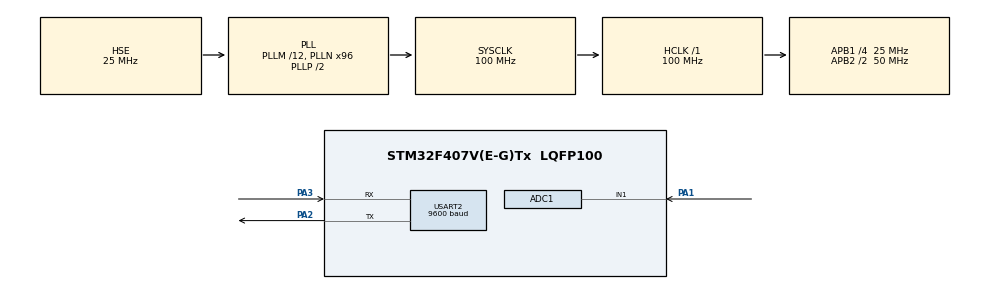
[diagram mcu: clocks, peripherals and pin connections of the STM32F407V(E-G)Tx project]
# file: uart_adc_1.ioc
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ADC1.Channel-0\#ChannelRegularConversion=ADC_CHANNEL_1
ADC1.EOCSelection=ADC_EOC_SEQ_CONV
ADC1.NbrOfConversionFlag=1
ADC1.Rank-0\#ChannelRegularConversion=1
ADC1.SamplingTime-0\#ChannelRegularConversion=ADC_SAMPLETIME_144CYCLES
ADC1.master=1
Mcu.Family=STM32F4
Mcu.Name=STM32F407V(E-G)Tx
Mcu.Package=LQFP100
NVIC.ADC_IRQn=true\:0\:0\:false\:false\:true\:true
NVIC.PriorityGroup=NVIC_PRIORITYGROUP_4
NVIC.USART2_IRQn=true\:0\:0\:false\:false\:true\:true
PA1.Signal=ADCx_IN1
PA2.Mode=Asynchronous
PA2.Signal=USART2_TX
PA3.Mode=Asynchronous
PA3.Signal=USART2_RX
PH0-OSC_IN.Mode=HSE-External-Oscillator
PH0-OSC_IN.Signal=RCC_OSC_IN
PH1-OSC_OUT.Mode=HSE-External-Oscillator
PH1-OSC_OUT.Signal=RCC_OSC_OUT
ProjectManager.HeapSize=0x200
ProjectManager.StackSize=0x400
ProjectManager.TargetToolchain=TrueSTUDIO
RCC.48MHZClocksFreq_Value=50000000
RCC.AHBFreq_Value=100000000
RCC.APB1CLKDivider=RCC_HCLK_DIV4
RCC.APB1Freq_Value=25000000
RCC.APB1TimFreq_Value=50000000
RCC.APB2CLKDivider=RCC_HCLK_DIV2
RCC.APB2Freq_Value=50000000
RCC.APB2TimFreq_Value=100000000
RCC.CortexFreq_Value=100000000
RCC.HCLKFreq_Value=100000000
RCC.HSE_VALUE=25000000
RCC.HSI_VALUE=16000000
RCC.LSE_VALUE=32768
RCC.PLLM=12
RCC.PLLN=96
RCC.PLLSourceVirtual=RCC_PLLSOURCE_HSE
RCC.SYSCLKFreq_VALUE=100000000
RCC.SYSCLKSource=RCC_SYSCLKSOURCE_PLLCLK
RCC.VCOOutputFreq_Value=200000000
SH.ADCx_IN1.0=ADC1_IN1,IN1
USART2.BaudRate=9600
USART2.VirtualMode=VM_ASYNC
board=uart_adc_1

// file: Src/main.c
/**
  ******************************************************************************
  * File Name          : main.c
  * Description        : Main program body
  ******************************************************************************
  ** This notice applies to any and all portions of this file
  * that are not between comment pairs USER CODE BEGIN and
  * USER CODE END. Other portions of this file, whether
  * inserted by the user or by software development tools
  * are owned by their respective copyright owners.
  *
  * COPYRIGHT(c) 2018 STMicroelectronics
  *
  * Redistribution and use in source and binary forms, with or without modification,
  * are permitted provided that the following conditions are met:
  *   1. Redistributions of source code must retain the above copyright notice,
  *      this list of conditions and the following disclaimer.
  *   2. Redistributions in binary form must reproduce the above copyright notice,
  *      this list of conditions and the following disclaimer in the documentation
  *      and/or other materials provided with the distribution.
  *   3. Neither the name of STMicroelectronics nor the names of its contributors
  *      may be used to endorse or promote products derived from this software
  *      without specific prior written permission.
  *
  * THIS SOFTWARE IS PROVIDED BY THE COPYRIGHT HOLDERS AND CONTRIBUTORS "AS IS"
  * AND ANY EXPRESS OR IMPLIED WARRANTIES, INCLUDING, BUT NOT LIMITED TO, THE
  * IMPLIED WARRANTIES OF MERCHANTABILITY AND FITNESS FOR A PARTICULAR PURPOSE ARE
  * DISCLAIMED. IN NO EVENT SHALL THE COPYRIGHT HOLDER OR CONTRIBUTORS BE LIABLE
  * FOR ANY DIRECT, INDIRECT, INCIDENTAL, SPECIAL, EXEMPLARY, OR CONSEQUENTIAL
  * DAMAGES (INCLUDING, BUT NOT LIMITED TO, PROCUREMENT OF SUBSTITUTE GOODS OR
  * SERVICES; LOSS OF USE, DATA, OR PROFITS; OR BUSINESS INTERRUPTION) HOWEVER
  * CAUSED AND ON ANY THEORY OF LIABILITY, WHETHER IN CONTRACT, STRICT LIABILITY,
  * OR TORT (INCLUDING NEGLIGENCE OR OTHERWISE) ARISING IN ANY WAY OUT OF THE USE
  * OF THIS SOFTWARE, EVEN IF ADVISED OF THE POSSIBILITY OF SUCH DAMAGE.
  *
  ******************************************************************************
  */

#include "main.h"
#include "stm32f4xx_hal.h"

/* USER CODE BEGIN Includes */

#define      M_TX_TASK          0
#define      M_RX_TASK          1
#define      M_TX_RX_TASK       2
#define      M_TASK1            3
#define      M_TASK2            4
#define      M_TASK3            5
#define      M_TASK4            6
#define      M_TASKS_UART       M_TASK4

/* USER CODE END Includes */

ADC_HandleTypeDef hadc1;

UART_HandleTypeDef huart2;

/* USER CODE BEGIN PV */
/* Private variables ---------------------------------------------------------*/

/* USER CODE END PV */

void SystemClock_Config(void);
static void MX_GPIO_Init(void);
static void MX_ADC1_Init(void);
static void MX_USART2_UART_Init(void);

/* USER CODE BEGIN PFP */
/* Private function prototypes -----------------------------------------------*/

/* USER CODE END PFP */

/* USER CODE BEGIN 0 */

uint16_t v_adcData_u16;
uint8_t a_rxBuffer_u8[20] = {0};

uint8_t i;

uint8_t* varToStrConv(uint16_t v_var_u16, uint8_t v_size_u8)
{
	static uint8_t p_string_u8[1000]= {0};
	int8_t v_cnt_u8;
	p_string_u8[v_size_u8 - 1] = '\n';
	for(v_cnt_u8 = (v_size_u8 - 2); v_cnt_u8 >= 0; v_cnt_u8--)
	{
	p_string_u8[v_cnt_u8] = ((v_var_u16 % 10) + 48);
	v_var_u16 /= 10;
	}

	return p_string_u8;
}

void HAL_ADC_ConvCpltCallback(ADC_HandleTypeDef* hadc)
{
	v_adcData_u16 = HAL_ADC_GetValue(hadc);
}

void HAL_UART_TxCpltCallback(UART_HandleTypeDef *huart)
{
	i++;
}
/* USER CODE END 0 */

int main(void)
{

  /* USER CODE BEGIN 1 */
uint8_t indx = 0;
uint16_t v_counter4Dig_u32 = 0;
  /* USER CODE END 1 */

  /* MCU Configuration----------------------------------------------------------*/

  /* Reset of all peripherals, Initializes the Flash interface and the Systick. */
  HAL_Init();

  /* Configure the system clock */
  SystemClock_Config();

  /* Initialize all configured peripherals */
  MX_GPIO_Init();
  MX_ADC1_Init();
  MX_USART2_UART_Init();

  /* USER CODE BEGIN 2 */

  HAL_ADC_Start_IT(&hadc1);

  /* USER CODE END 2 */

  /* Infinite loop */
  while (1)
  {

  /* USER CODE BEGIN 3 */
#if(M_TASKS_UART == M_TX_TASK)
	  {
	   HAL_UART_Transmit_IT(&huart2, "hello\n", 6);

	  }
#endif

#if(M_TASKS_UART == M_RX_TASK)
	  {
	  HAL_UART_Receive_IT(&huart2, a_rxBuffer_u8, 20);
	  for(indx = 0; indx < 20 ; indx++)
	  {
		if(a_rxBuffer_u8[indx]  == 0)
			a_rxBuffer_u8[indx] = ' ';
	  }
	  a_rxBuffer_u8[19] = '\n';
	  HAL_UART_Transmit_IT(&huart2,a_rxBuffer_u8 , 20);
	  HAL_Delay(1000);
	  }
#endif

#if(M_TASKS_UART == M_TX_RX_TASK)
	  {
	   HAL_UART_Transmit_IT(&huart2, "hello\n", 6);
	   HAL_Delay(500);
	  HAL_UART_Receive_IT(&huart2, a_rxBuffer_u8, 20);
	  for(indx = 0; indx < 20 ; indx++)
	  {
		if(a_rxBuffer_u8[indx]  == 0)
			a_rxBuffer_u8[indx] = ' ';
	  }
	  a_rxBuffer_u8[19] = '\n';
	  HAL_UART_Transmit_IT(&huart2,a_rxBuffer_u8 , 20);
	  HAL_Delay(500);
	  }
#endif

#if(M_TASKS_UART == M_TASK1)
	  {
		  HAL_UART_Transmit_IT(&huart2, "hello\n", 6);
		  HAL_Delay(100);
	  }
#endif

#if(M_TASKS_UART == M_TASK2)
	  {
		  HAL_UART_Transmit_IT(&huart2, varToStrConv(v_counter4Dig_u32++,5), 5);
		  HAL_Delay(100);
	  }
#endif

#if(M_TASKS_UART == M_TASK3)
	  {
		  HAL_UART_Receive_IT(&huart2, a_rxBuffer_u8, 1);
		  HAL_UART_Transmit_IT(&huart2, varToStrConv(a_rxBuffer_u8[0],4), 4);
		  HAL_Delay(100);
	  }
#endif

#if(M_TASKS_UART == M_TASK4)
	  {
		  HAL_UART_Transmit_IT(&huart2, "hello\n", 6);
		  //varToStrConv(v_adcData_u16, 5)
	  }
#endif

  }
  /* USER CODE END 3 */

}

/** System Clock Configuration
*/
void SystemClock_Config(void)
{

  RCC_OscInitTypeDef RCC_OscInitStruct;
  RCC_ClkInitTypeDef RCC_ClkInitStruct;

    /**Configure the main internal regulator output voltage
    */
  __HAL_RCC_PWR_CLK_ENABLE();

  __HAL_PWR_VOLTAGESCALING_CONFIG(PWR_REGULATOR_VOLTAGE_SCALE1);

    /**Initializes the CPU, AHB and APB busses clocks
    */
  RCC_OscInitStruct.OscillatorType = RCC_OSCILLATORTYPE_HSE;
  RCC_OscInitStruct.HSEState = RCC_HSE_ON;
  RCC_OscInitStruct.PLL.PLLState = RCC_PLL_ON;
  RCC_OscInitStruct.PLL.PLLSource = RCC_PLLSOURCE_HSE;
  RCC_OscInitStruct.PLL.PLLM = 12;
  RCC_OscInitStruct.PLL.PLLN = 96;
  RCC_OscInitStruct.PLL.PLLP = RCC_PLLP_DIV2;
  RCC_OscInitStruct.PLL.PLLQ = 4;
  if (HAL_RCC_OscConfig(&RCC_OscInitStruct) != HAL_OK)
  {
    _Error_Handler(__FILE__, __LINE__);
  }

    /**Initializes the CPU, AHB and APB busses clocks
    */
  RCC_ClkInitStruct.ClockType = RCC_CLOCKTYPE_HCLK|RCC_CLOCKTYPE_SYSCLK
                              |RCC_CLOCKTYPE_PCLK1|RCC_CLOCKTYPE_PCLK2;
  RCC_ClkInitStruct.SYSCLKSource = RCC_SYSCLKSOURCE_PLLCLK;
  RCC_ClkInitStruct.AHBCLKDivider = RCC_SYSCLK_DIV1;
  RCC_ClkInitStruct.APB1CLKDivider = RCC_HCLK_DIV4;
  RCC_ClkInitStruct.APB2CLKDivider = RCC_HCLK_DIV2;

  if (HAL_RCC_ClockConfig(&RCC_ClkInitStruct, FLASH_LATENCY_3) != HAL_OK)
  {
    _Error_Handler(__FILE__, __LINE__);
  }

    /**Configure the Systick interrupt time
    */
  HAL_SYSTICK_Config(HAL_RCC_GetHCLKFreq()/1000);

    /**Configure the Systick
    */
  HAL_SYSTICK_CLKSourceConfig(SYSTICK_CLKSOURCE_HCLK);

  /* SysTick_IRQn interrupt configuration */
  HAL_NVIC_SetPriority(SysTick_IRQn, 0, 0);
}

/* ADC1 init function */
static void MX_ADC1_Init(void)
{

  ADC_ChannelConfTypeDef sConfig;

    /**Configure the global features of the ADC (Clock, Resolution, Data Alignment and number of conversion)
    */
  hadc1.Instance = ADC1;
  hadc1.Init.ClockPrescaler = ADC_CLOCK_SYNC_PCLK_DIV2;
  hadc1.Init.Resolution = ADC_RESOLUTION_12B;
  hadc1.Init.ScanConvMode = DISABLE;
  hadc1.Init.ContinuousConvMode = DISABLE;
  hadc1.Init.DiscontinuousConvMode = DISABLE;
  hadc1.Init.ExternalTrigConvEdge = ADC_EXTERNALTRIGCONVEDGE_NONE;
  hadc1.Init.ExternalTrigConv = ADC_SOFTWARE_START;
  hadc1.Init.DataAlign = ADC_DATAALIGN_RIGHT;
  hadc1.Init.NbrOfConversion = 1;
  hadc1.Init.DMAContinuousRequests = DISABLE;
  hadc1.Init.EOCSelection = ADC_EOC_SEQ_CONV;
  if (HAL_ADC_Init(&hadc1) != HAL_OK)
  {
    _Error_Handler(__FILE__, __LINE__);
  }

    /**Configure for the selected ADC regular channel its corresponding rank in the sequencer and its sample time.
    */
  sConfig.Channel = ADC_CHANNEL_1;
  sConfig.Rank = 1;
  sConfig.SamplingTime = ADC_SAMPLETIME_144CYCLES;
  if (HAL_ADC_ConfigChannel(&hadc1, &sConfig) != HAL_OK)
  {
    _Error_Handler(__FILE__, __LINE__);
  }

}

/* USART2 init function */
static void MX_USART2_UART_Init(void)
{

  huart2.Instance = USART2;
  huart2.Init.BaudRate = 9600;
  huart2.Init.WordLength = UART_WORDLENGTH_8B;
  huart2.Init.StopBits = UART_STOPBITS_1;
  huart2.Init.Parity = UART_PARITY_NONE;
  huart2.Init.Mode = UART_MODE_TX_RX;
  huart2.Init.HwFlowCtl = UART_HWCONTROL_NONE;
  huart2.Init.OverSampling = UART_OVERSAMPLING_16;
  if (HAL_UART_Init(&huart2) != HAL_OK)
  {
    _Error_Handler(__FILE__, __LINE__);
  }

}

/** Configure pins as
        * Analog
        * Input
        * Output
        * EVENT_OUT
        * EXTI
*/
static void MX_GPIO_Init(void)
{

  /* GPIO Ports Clock Enable */
  __HAL_RCC_GPIOH_CLK_ENABLE();
  __HAL_RCC_GPIOA_CLK_ENABLE();

}

void _Error_Handler(char * file, int line)
{
  while(1)
  {
  }
}

/************************ (C) COPYRIGHT STMicroelectronics *****END OF FILE****/
